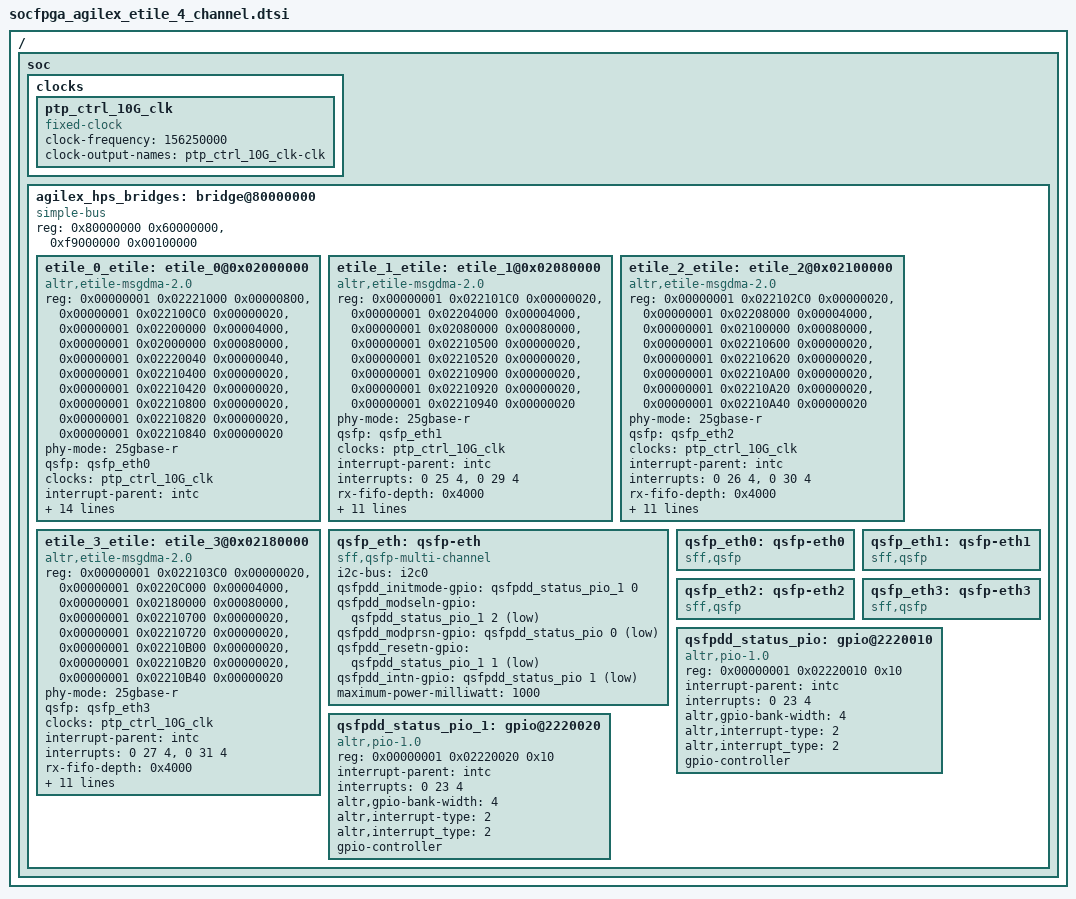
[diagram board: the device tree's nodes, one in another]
// SPDX-License-Identifier: GPL-2.0
/*
 * Copyright(C) 2022, Intel Corporation
 */

/* Add this piece of dtsi fragment as #include "socfpga_agilex_etile_4_channel.dtsi"
 * in the file socfpga_agilex_socdk.dts. Compile it in the kernel along with
 * socfpga_agilex.dtsi and in 4 channel design rsfec and tod_ctrl should be mapped 
 * for fec-cw-pos-rx <lane 0>
 */

/{
	soc {
		clocks {
			ptp_ctrl_10G_clk: ptp_ctrl_10G_clk {
				#clock-cells = <0>;
				compatible = "fixed-clock";
				clock-frequency = <156250000>;
				clock-output-names = "ptp_ctrl_10G_clk-clk";
			};
		};

		agilex_hps_bridges: bridge@80000000 {
			compatible = "simple-bus";
			reg = <0x80000000 0x60000000>,
				<0xf9000000 0x00100000>;
			reg-names = "axi_h2f", "axi_h2f_lw";
			#address-cells = <0x2>;
			#size-cells = <0x1>;
			ranges = <0x00000000 0x00000000 0xf9000000 0x00100000>,
				<0x00000001 0x02220010 0x82220010 0x00000010>,
				<0x00000001 0x02220020 0x82220020 0x00000010>,
				<0x00000001 0x02221000 0x82221000 0x00000800>,
				<0x00000001 0x02220040 0x82220040 0x00000020>,
				<0x00000001 0x022100C0 0x822100C0 0x00000020>,				
				<0x00000001 0x02200000 0x82200000 0x00004000>,
				<0x00000001 0x02000000 0x82000000 0x00080000>,				
				<0x00000001 0x02210400 0x82210400 0x00000020>,
				<0x00000001 0x02210420 0x82210420 0x00000020>,
				<0x00000001 0x02210800 0x82210800 0x00000020>,
				<0x00000001 0x02210820 0x82210820 0x00000020>,
				<0x00000001 0x02210840 0x82210840 0x00000020>,	
				<0x00000001 0x022102C0 0x822102C0 0x00000020>,
				<0x00000001 0x02208000 0x82208000 0x00004000>,
				<0x00000001 0x02100000 0x82100000 0x00080000>,				
				<0x00000001 0x02210600 0x82210600 0x00000020>,
				<0x00000001 0x02210620 0x82210620 0x00000020>,
				<0x00000001 0x02210A00 0x82210A00 0x00000020>,
				<0x00000001 0x02210A20 0x82210A20 0x00000020>,
				<0x00000001 0x02210A40 0x82210A40 0x00000020>,
				<0x00000001 0x022101C0 0x822101C0 0x00000020>,
				<0x00000001 0x02204000 0x82204000 0x00004000>,
				<0x00000001 0x02080000 0x82080000 0x00080000>,				
				<0x00000001 0x02210500 0x82210500 0x00000020>,
				<0x00000001 0x02210520 0x82210520 0x00000020>,
				<0x00000001 0x02210900 0x82210900 0x00000020>,
				<0x00000001 0x02210920 0x82210920 0x00000020>,
				<0x00000001 0x02210940 0x82210940 0x00000020>,
				<0x00000001 0x022103C0 0x822103C0 0x00000020>,
				<0x00000001 0x0220C000 0x8220C000 0x00004000>,
				<0x00000001 0x02180000 0x82180000 0x00080000>,				
				<0x00000001 0x02210700 0x82210700 0x00000020>,
				<0x00000001 0x02210720 0x82210720 0x00000020>,
				<0x00000001 0x02210B00 0x82210B00 0x00000020>,
				<0x00000001 0x02210B20 0x82210B20 0x00000020>,
				<0x00000001 0x02210B40 0x82210B40 0x00000020>,											
				<0x00000001 0x00000300 0xf9000300 0x00000010>,
				<0x00000001 0x02000000 0x82000000 0x00000010>;
				
			etile_0_etile: etile_0@0x02000000 {
				compatible = "altr,etile-msgdma-2.0";				
				reg-names =  "rsfec","tod_pio","eth_reconfig", "xcvr", "tod_ctrl",
						"tx_pref", "tx_csr", "rx_pref", "rx_csr",
						"rx_fifo";				
				reg =     <0x00000001 0x02221000 0x00000800>,
					 <0x00000001 0x022100C0 0x00000020>,
					  <0x00000001 0x02200000 0x00004000>,
					  <0x00000001 0x02000000 0x00080000>,
					  <0x00000001 0x02220040 0x00000040>,
					  <0x00000001 0x02210400 0x00000020>,
					  <0x00000001 0x02210420 0x00000020>,
					  <0x00000001 0x02210800 0x00000020>,
					  <0x00000001 0x02210820 0x00000020>,
					  <0x00000001 0x02210840 0x00000020>;					
					  
				//dma-coherent;
				phy-mode = "25gbase-r";
				qsfp = <&qsfp_eth0>;
				clocks = <&ptp_ctrl_10G_clk>;
				clock-names = "tod_clk";
				interrupt-parent = <&intc>;
				interrupt-names = "tx_irq", "rx_irq";
				interrupts = <0 24 4>,
						<0 28 4>;
				rx-fifo-depth = <0x4000>;
				tx-fifo-depth = <0x1000>;
				rx-fifo-almost-full = <0x2000>;
				rx-fifo-almost-empty = <0x1000>;
				//local-mac-address = [fa b1 0a 12 72 44];
				altr,tx-pma-delay-ns = <0xD>;
				altr,rx-pma-delay-ns = <0x8>;
				altr,tx-pma-delay-fns = <0x24D>;
				altr,rx-pma-delay-fns = <0x3E97>;
				altr,tx-external-phy-delay-ns = <0x0>;
				altr,rx-external-phy-delay-ns = <0x0>;
				fec-type = "kr-fec";
				fec-cw-pos-rx = <0>;
				altr,has-ptp;
				status = "okay";
			};

			etile_1_etile: etile_1@0x02080000 {
				compatible = "altr,etile-msgdma-2.0";				
				reg-names = "tod_pio","eth_reconfig", "xcvr", 
						"tx_pref", "tx_csr", "rx_pref", "rx_csr",
						"rx_fifo";				
				reg =   <0x00000001 0x022101C0 0x00000020>,  
					<0x00000001 0x02204000 0x00004000>,
					  <0x00000001 0x02080000 0x00080000>,					 
					  <0x00000001 0x02210500 0x00000020>,
					  <0x00000001 0x02210520 0x00000020>,
					  <0x00000001 0x02210900 0x00000020>,
					  <0x00000001 0x02210920 0x00000020>,
					 <0x00000001 0x02210940 0x00000020>;				
				//dma-coherent;
				phy-mode = "25gbase-r";
				qsfp = <&qsfp_eth1>;
				clocks = <&ptp_ctrl_10G_clk>;
				clock-names = "tod_clk";
				interrupt-parent = <&intc>;
				interrupt-names = "tx_irq", "rx_irq";
				interrupts = <0 25 4>,
						<0 29 4>;
				rx-fifo-depth = <0x4000>;
				tx-fifo-depth = <0x1000>;
				rx-fifo-almost-full = <0x2000>;
				rx-fifo-almost-empty = <0x1000>;
				//local-mac-address = [fa b1 0a 12 72 44];
				altr,tx-pma-delay-ns = <0xD>;
				altr,rx-pma-delay-ns = <0x8>;
				altr,tx-pma-delay-fns = <0x24D>;
				altr,rx-pma-delay-fns = <0x3E97>;
				altr,tx-external-phy-delay-ns = <0x0>;
				altr,rx-external-phy-delay-ns = <0x0>;
				fec-type = "kr-fec";
				fec-cw-pos-rx = <1>;
				//altr,has-ptp;
				status = "okay";
			};

			etile_2_etile: etile_2@0x02100000 {
				compatible = "altr,etile-msgdma-2.0";				
				reg-names = "tod_pio", "eth_reconfig", "xcvr", 
						"tx_pref", "tx_csr", "rx_pref", "rx_csr",
						"rx_fifo";				
				reg =    <0x00000001 0x022102C0 0x00000020>, 
					<0x00000001 0x02208000 0x00004000>,
					  <0x00000001 0x02100000 0x00080000>,					  
					  <0x00000001 0x02210600 0x00000020>,
					  <0x00000001 0x02210620 0x00000020>,
					  <0x00000001 0x02210A00 0x00000020>,
					  <0x00000001 0x02210A20 0x00000020>,
					  <0x00000001 0x02210A40 0x00000020>;
				//dma-coherent;
				phy-mode = "25gbase-r";
				qsfp = <&qsfp_eth2>;
				clocks = <&ptp_ctrl_10G_clk>;
				clock-names = "tod_clk";
				interrupt-parent = <&intc>;
				interrupt-names = "tx_irq", "rx_irq";
				interrupts = <0 26 4>,
						<0 30 4>;
				rx-fifo-depth = <0x4000>;
				tx-fifo-depth = <0x1000>;
				rx-fifo-almost-full = <0x2000>;
				rx-fifo-almost-empty = <0x1000>;
				//local-mac-address = [fa b1 0a 12 72 44];
				altr,tx-pma-delay-ns = <0xD>;
				altr,rx-pma-delay-ns = <0x8>;
				altr,tx-pma-delay-fns = <0x24D>;
				altr,rx-pma-delay-fns = <0x3E97>;
				altr,tx-external-phy-delay-ns = <0x0>;
				altr,rx-external-phy-delay-ns = <0x0>;
				fec-type = "kr-fec";
				fec-cw-pos-rx = <2>;
				//altr,has-ptp;
				status = "okay";
			};

				etile_3_etile: etile_3@0x02180000 {
				compatible = "altr,etile-msgdma-2.0";
				reg-names = "tod_pio", "eth_reconfig", "xcvr", 
						"tx_pref", "tx_csr", "rx_pref", "rx_csr",
						"rx_fifo";
				reg = 	<0x00000001 0x022103C0 0x00000020>, 
					<0x00000001 0x0220C000 0x00004000>,
					<0x00000001 0x02180000 0x00080000>,										
					<0x00000001 0x02210700 0x00000020>,
					<0x00000001 0x02210720 0x00000020>,
					<0x00000001 0x02210B00 0x00000020>,
					<0x00000001 0x02210B20 0x00000020>,
					<0x00000001 0x02210B40 0x00000020>;
				//dma-coherent;
				phy-mode = "25gbase-r";
				qsfp = <&qsfp_eth3>;
				clocks = <&ptp_ctrl_10G_clk>;
				clock-names = "tod_clk";
				interrupt-parent = <&intc>;
				interrupt-names = "tx_irq", "rx_irq";
				interrupts = <0 27 4>,
						<0 31 4>;
				rx-fifo-depth = <0x4000>;
				tx-fifo-depth = <0x1000>;
				rx-fifo-almost-full = <0x2000>;
				rx-fifo-almost-empty = <0x1000>;
				//local-mac-address = [fa b1 0a 12 72 44];
				altr,tx-pma-delay-ns = <0xD>;
				altr,rx-pma-delay-ns = <0x8>;
				altr,tx-pma-delay-fns = <0x24D>;
				altr,rx-pma-delay-fns = <0x3E97>;
				altr,tx-external-phy-delay-ns = <0x0>;
				altr,rx-external-phy-delay-ns = <0x0>;
				fec-type = "kr-fec";
				fec-cw-pos-rx = <3>;
				//altr,has-ptp;
				status = "okay";
			};				

			qsfp_eth: qsfp-eth {
				compatible = "sff,qsfp-multi-channel";
				i2c-bus = <&i2c0>;
				qsfpdd_initmode-gpio = <&qsfpdd_status_pio_1 0 GPIO_ACTIVE_HIGH>;
				qsfpdd_modseln-gpio = <&qsfpdd_status_pio_1 2 GPIO_ACTIVE_LOW>;
				qsfpdd_modprsn-gpio = <&qsfpdd_status_pio 0 GPIO_ACTIVE_LOW>;
				qsfpdd_resetn-gpio = <&qsfpdd_status_pio_1 1 GPIO_ACTIVE_LOW>;
				qsfpdd_intn-gpio = <&qsfpdd_status_pio 1 GPIO_ACTIVE_LOW>;
				maximum-power-milliwatt = <1000>;
				status = "okay";
			};
			
			qsfp_eth0: qsfp-eth0 {
				compatible = "sff,qsfp";
				status = "okay";
			};
			
			qsfp_eth1: qsfp-eth1 {
				compatible = "sff,qsfp";
				status = "okay";
			};
			
			qsfp_eth2: qsfp-eth2 {
				compatible = "sff,qsfp";
				status = "okay";
			};
			
			qsfp_eth3: qsfp-eth3 {
				compatible = "sff,qsfp";
				status = "okay";
			};			
	

			qsfpdd_status_pio: gpio@2220010 {
				compatible = "altr,pio-1.0";
				reg = <0x00000001 0x02220010 0x10>;
				interrupt-parent = <&intc>;
				interrupts = <0 23 4>;
				altr,gpio-bank-width = <4>;
				altr,interrupt-type = <2>;
				altr,interrupt_type = <2>;
				#gpio-cells = <2>;
				gpio-controller;
				status = "okay";
			};

			qsfpdd_status_pio_1: gpio@2220020 {
				compatible = "altr,pio-1.0";
				reg = <0x00000001 0x02220020 0x10>;
				interrupt-parent = <&intc>;
				interrupts = <0 23 4>;
				altr,gpio-bank-width = <4>;
				altr,interrupt-type = <2>;
				altr,interrupt_type = <2>;
				#gpio-cells = <2>;
				gpio-controller;
				status = "okay";
			};
		};

	};
};
